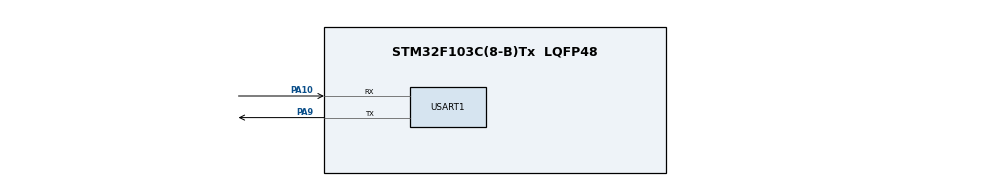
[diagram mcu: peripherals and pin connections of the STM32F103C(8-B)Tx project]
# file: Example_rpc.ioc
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FREERTOS.BinarySemaphores01=GetPacketSem,Dynamic,NULL;SendPacketSem,Dynamic,NULL
FREERTOS.Queues01=rxQueue,16,uint16_t,0,Dynamic,NULL,NULL
FREERTOS.Tasks01=defaultTask,0,128,StartDefaultTask,Default,NULL,Dynamic,NULL,NULL;linkLayerTask,2,512,LinkLayerReceive,Default,NULL,Dynamic,NULL,NULL;transpRecTask,2,512,TranspReceive,Default,NULL,Dynamic,NULL,NULL
FREERTOS.configTOTAL_HEAP_SIZE=10000
Mcu.Family=STM32F1
Mcu.Name=STM32F103C(8-B)Tx
Mcu.Package=LQFP48
NVIC.PriorityGroup=NVIC_PRIORITYGROUP_4
NVIC.TIM1_UP_IRQn=true\:15\:0\:false\:false\:true\:false\:false\:true
NVIC.TimeBase=TIM1_UP_IRQn
NVIC.TimeBaseIP=TIM1
NVIC.USART1_IRQn=true\:5\:0\:false\:false\:true\:true\:true\:true
PA10.Mode=Asynchronous
PA10.Signal=USART1_RX
PA13.Mode=Serial_Wire
PA13.Signal=SYS_JTMS-SWDIO
PA14.Mode=Serial_Wire
PA14.Signal=SYS_JTCK-SWCLK
PA9.Mode=Asynchronous
PA9.Signal=USART1_TX
PC14-OSC32_IN.Mode=LSE-External-Oscillator
PC14-OSC32_IN.Signal=RCC_OSC32_IN
PC15-OSC32_OUT.Mode=LSE-External-Oscillator
PC15-OSC32_OUT.Signal=RCC_OSC32_OUT
PD0-OSC_IN.Mode=HSE-External-Oscillator
PD0-OSC_IN.Signal=RCC_OSC_IN
PD1-OSC_OUT.Mode=HSE-External-Oscillator
PD1-OSC_OUT.Signal=RCC_OSC_OUT
ProjectManager.HeapSize=0x200
ProjectManager.StackSize=0x400
ProjectManager.TargetToolchain=STM32CubeIDE
RCC.APB1Freq_Value=8000000
RCC.APB2Freq_Value=8000000
USART1.VirtualMode=VM_ASYNC
VP_FREERTOS_VS_CMSIS_V1.Mode=CMSIS_V1
VP_SYS_VS_tim1.Mode=TIM1
board=custom

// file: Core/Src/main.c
/* USER CODE BEGIN Header */
/**
  ******************************************************************************
  * @file           : main.c
  * @brief          : Main program body
  ******************************************************************************
  * @attention
  *
  * Copyright (c) 2025 STMicroelectronics.
  * All rights reserved.
  *
  * This software is licensed under terms that can be found in the LICENSE file
  * in the root directory of this software component.
  * If no LICENSE file comes with this software, it is provided AS-IS.
  *
  ******************************************************************************
  */
/* USER CODE END Header */
#include "main.h"
#include "cmsis_os.h"
#include "usart.h"
#include "gpio.h"

void SystemClock_Config(void);
void MX_FREERTOS_Init(void);

int main(void)
{

  /* MCU Configuration--------------------------------------------------------*/

  /* Reset of all peripherals, Initializes the Flash interface and the Systick. */
  HAL_Init();

  /* Configure the system clock */
  SystemClock_Config();

  /* Initialize all configured peripherals */
  MX_GPIO_Init();
  MX_USART1_UART_Init();
  /* USER CODE BEGIN 2 */
  HAL_UARTEx_ReceiveToIdle_IT(&huart1, Buffer, 128);
  /* USER CODE END 2 */

  /* Call init function for freertos objects (in freertos.c) */
  MX_FREERTOS_Init();
  /* Start scheduler */
  osKernelStart();

  /* We should never get here as control is now taken by the scheduler */
  /* Infinite loop */
  while (1)
  {

  }
}

void SystemClock_Config(void)
{
  RCC_OscInitTypeDef RCC_OscInitStruct = {0};
  RCC_ClkInitTypeDef RCC_ClkInitStruct = {0};

  /** Initializes the RCC Oscillators according to the specified parameters
  * in the RCC_OscInitTypeDef structure.
  */
  RCC_OscInitStruct.OscillatorType = RCC_OSCILLATORTYPE_HSI;
  RCC_OscInitStruct.HSIState = RCC_HSI_ON;
  RCC_OscInitStruct.HSICalibrationValue = RCC_HSICALIBRATION_DEFAULT;
  RCC_OscInitStruct.PLL.PLLState = RCC_PLL_NONE;
  if (HAL_RCC_OscConfig(&RCC_OscInitStruct) != HAL_OK)
  {
    Error_Handler();
  }
  /** Initializes the CPU, AHB and APB buses clocks
  */
  RCC_ClkInitStruct.ClockType = RCC_CLOCKTYPE_HCLK|RCC_CLOCKTYPE_SYSCLK
                              |RCC_CLOCKTYPE_PCLK1|RCC_CLOCKTYPE_PCLK2;
  RCC_ClkInitStruct.SYSCLKSource = RCC_SYSCLKSOURCE_HSI;
  RCC_ClkInitStruct.AHBCLKDivider = RCC_SYSCLK_DIV1;
  RCC_ClkInitStruct.APB1CLKDivider = RCC_HCLK_DIV1;
  RCC_ClkInitStruct.APB2CLKDivider = RCC_HCLK_DIV1;

  if (HAL_RCC_ClockConfig(&RCC_ClkInitStruct, FLASH_LATENCY_0) != HAL_OK)
  {
    Error_Handler();
  }
}

void HAL_TIM_PeriodElapsedCallback(TIM_HandleTypeDef *htim)
{
  if (htim->Instance == TIM1) {
    HAL_IncTick();
  }
}

void Error_Handler(void)
{
  __disable_irq();
  while (1)
  {
  }
}

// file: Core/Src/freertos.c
/* USER CODE BEGIN Header */
/**
  ******************************************************************************
  * File Name          : freertos.c
  * Description        : Code for freertos applications
  ******************************************************************************
  * @attention
  *
  * Copyright (c) 2025 STMicroelectronics.
  * All rights reserved.
  *
  * This software is licensed under terms that can be found in the LICENSE file
  * in the root directory of this software component.
  * If no LICENSE file comes with this software, it is provided AS-IS.
  *
  ******************************************************************************
  */
/* USER CODE END Header */

#include "FreeRTOS.h"
#include "task.h"
#include "main.h"
#include "cmsis_os.h"

/* USER CODE BEGIN PTD */
extern UART_HandleTypeDef huart1;
/* USER CODE END PTD */

/* USER CODE BEGIN PD */
#define MAX_PACKET_SIZE 128

uint8_t crc8_calc(const uint8_t *data, uint16_t len);
bool uart_send(const uint8_t *data, uint16_t len);
bool link_layer_send(const uint8_t *payload, uint16_t payload_len);
bool transport_call(const char *name, const uint8_t *args, uint16_t args_len,
		uint8_t *resp, uint16_t *resp_len, uint32_t timeout);

void getTemp(const uint8_t* args, uint16_t args_len,uint8_t* resp, uint16_t* resp_len);
void getPressure(const uint8_t* args, uint16_t args_len,uint8_t* resp, uint16_t* resp_len);
void send_response(uint8_t seq,  uint8_t* data, uint16_t len) ;
void send_error(uint8_t seq, uint8_t error_code);

typedef void (*RPCFunction)(const uint8_t*, uint16_t, uint8_t*, uint16_t*);

typedef struct {
    uint8_t data[MAX_PACKET_SIZE];
    uint16_t length;
} Packet_t;

typedef struct {
    const char *name;
    RPCFunction func;
} FunctionEntry;

FunctionEntry functions[2] = {
		{"Get Temp",getTemp},
		{"Get Pressure",getPressure}
};
uint8_t func_count = 2;
uint8_t seq_counter = 0;
/* USER CODE END PD */

/* USER CODE BEGIN PM */

void getTemp(const uint8_t* args, uint16_t args_len,uint8_t* resp, uint16_t* resp_len)
{
	// Функция получения температуры
}
void getPressure(const uint8_t* args, uint16_t args_len, uint8_t* resp, uint16_t* resp_len)
{
	// Функция установки температуры
}

void send_response(uint8_t seq, uint8_t* data, uint16_t len)
{
    uint8_t payload[2 + len];
    payload[0] = RESPONSE; // RESPONSE
    payload[1] = seq;
    memcpy(&payload[2], data, len);
    link_layer_send(payload, 2 + len);
}

void send_error(uint8_t seq, uint8_t error_code)
{
    uint8_t payload[3];
    payload[0] = ERR;
    payload[1] = seq;
    payload[2] = error_code;
    link_layer_send(payload, 3);
}

uint8_t crc8_calc(const uint8_t *data, uint16_t len)
{
    uint8_t crc = 0x00;
    while (len--) {
        crc ^= *data++;
        for (uint8_t i = 0; i < 8; i++)
            crc = (crc & 0x80) ? ((crc << 1) ^ 0x07) : (crc << 1);
    }
    return crc;
}

bool uart_send(const uint8_t *data, uint16_t len)
{
    return HAL_UART_Transmit(&huart1, (uint8_t*)data, len, 10) == HAL_OK;
}

bool link_layer_send(const uint8_t *payload, uint16_t payload_len)
{
    // Проверка максимального размера
    if (payload_len > MAX_PACKET_SIZE - 7) return false;

    uint8_t packet[MAX_PACKET_SIZE];
    uint16_t l = 6 + payload_len;  // Длина части после 0xFA

    // Формирование заголовка
    packet[0] = 0xFA;              // Стартовый байт 1
    packet[1] = l & 0xFF;           // Младший байт длины
    packet[2] = (l >> 8) & 0xFF;    // Старший байт длины
    packet[3] = crc8_calc(&packet[1], 2); // CRC заголовка (байты 1-2)
    packet[4] = 0xFB;              // Стартовый байт 2

    // Копирование полезной нагрузки
    memcpy(&packet[5], payload, payload_len);

    // Расчет CRC всего пакета (байты 0-4 + payload)
    uint8_t crc_full = crc8_calc(packet, 5 + payload_len);
    packet[5 + payload_len] = crc_full;   // CRC payload
    packet[6 + payload_len] = 0xFE;       // Стоповый байт

    // Отправка через физический уровень
    return uart_send(packet, 7 + payload_len);
}

/* USER CODE END PM */

osThreadId defaultTaskHandle;
osThreadId linkLayerTaskHandle;
osThreadId transpRecTaskHandle;
osMessageQId rxQueueHandle;
osSemaphoreId GetPacketSemHandle;
osSemaphoreId SendPacketSemHandle;

void StartDefaultTask(void const * argument);
void LinkLayerReceive(void const * argument);
void TranspReceive(void const * argument);

void MX_FREERTOS_Init(void); /* (MISRA C 2004 rule 8.1) */

/* GetIdleTaskMemory prototype (linked to static allocation support) */
void vApplicationGetIdleTaskMemory( StaticTask_t **ppxIdleTaskTCBBuffer, StackType_t **ppxIdleTaskStackBuffer, uint32_t *pulIdleTaskStackSize );

/* USER CODE BEGIN GET_IDLE_TASK_MEMORY */
static StaticTask_t xIdleTaskTCBBuffer;
static StackType_t xIdleStack[configMINIMAL_STACK_SIZE];

void vApplicationGetIdleTaskMemory( StaticTask_t **ppxIdleTaskTCBBuffer, StackType_t **ppxIdleTaskStackBuffer, uint32_t *pulIdleTaskStackSize )
{
  *ppxIdleTaskTCBBuffer = &xIdleTaskTCBBuffer;
  *ppxIdleTaskStackBuffer = &xIdleStack[0];
  *pulIdleTaskStackSize = configMINIMAL_STACK_SIZE;
  /* place for user code */
}
/* USER CODE END GET_IDLE_TASK_MEMORY */

void MX_FREERTOS_Init(void) {

  /* Create the semaphores(s) */
  /* definition and creation of GetPacketSem */
  osSemaphoreDef(GetPacketSem);
  GetPacketSemHandle = osSemaphoreCreate(osSemaphore(GetPacketSem), 1);
  osSemaphoreWait(GetPacketSemHandle, osWaitForever);
  /* definition and creation of SendPacketSem */
  osSemaphoreDef(SendPacketSem);
  SendPacketSemHandle = osSemaphoreCreate(osSemaphore(SendPacketSem), 1);
  osSemaphoreWait(SendPacketSemHandle, osWaitForever);

  /* Create the queue(s) */
  /* definition and creation of rxQueue */
  osMessageQDef(rxQueue, 16, uint16_t);
  rxQueueHandle = osMessageCreate(osMessageQ(rxQueue), NULL);

  /* Create the thread(s) */
  /* definition and creation of defaultTask */
  osThreadDef(defaultTask, StartDefaultTask, osPriorityNormal, 0, 128);
  defaultTaskHandle = osThreadCreate(osThread(defaultTask), NULL);

  /* definition and creation of linkLayerTask */
  osThreadDef(linkLayerTask, LinkLayerReceive, osPriorityHigh, 0, 512);
  linkLayerTaskHandle = osThreadCreate(osThread(linkLayerTask), NULL);

  /* definition and creation of transpRecTask */
  osThreadDef(transpRecTask, TranspReceive, osPriorityHigh, 0, 512);
  transpRecTaskHandle = osThreadCreate(osThread(transpRecTask), NULL);

}

void StartDefaultTask(void const * argument)
{
  /* USER CODE BEGIN StartDefaultTask */
  /* Infinite loop */
  for(;;)
  {
    osDelay(1000);
  }
  /* USER CODE END StartDefaultTask */
}

void LinkLayerReceive(void const * argument)
{
  /* USER CODE BEGIN LinkLayerReceive */
    //uint8_t buffer[MAX_PACKET_SIZE];
    uint16_t length = 0, index = 0;
    uint8_t expected_crc;
    uint8_t eStatus;
    Packet_t packet;
  /* Infinite loop */
  for(;;)
  {
	osSemaphoreWait(GetPacketSemHandle, osWaitForever);

	if(Buffer[0] == 0xFA)
	{
		expected_crc = crc8_calc(&Buffer[1], 2);

		 if(expected_crc == Buffer[3])
		 {
			 length = Buffer[2]<<8 |Buffer[1];
			 index = 0;

			 if( Buffer[3] == 0xFB)
			 {
				 for(uint8_t i = 5 ;  i < length - 2 ; i++) // Учет CRC и 0xFE
				 {
					 packet.data[index++] = Buffer[i];
				 }

				 packet.length = index;

				 expected_crc = crc8_calc(&Buffer[0],length - 2);

				 if(expected_crc == Buffer[length - 2] && Buffer[length - 1] == 0xFE)
				 {
					 // Успешный прием пакета
					 eStatus = xQueueSend(rxQueueHandle, &packet, 0);
				 }
			 }

		 }
	}

	if(eStatus == 0)
	send_error(0,ERR_INVALID_ARGS); // Отправка ошибки

    osDelay(1000);
  }
  /* USER CODE END LinkLayerReceive */
}

void TranspReceive(void const * argument)
{
  /* USER CODE BEGIN TranspReceive */

  /* Infinite loop */
  for(;;)
  {
	  uint8_t packet[MAX_PACKET_SIZE];
	  uint8_t packet_len;

	  if(xQueueReceive(rxQueueHandle, &packet, portMAX_DELAY))
	  {
		 uint32_t start_time = xTaskGetTickCount();

		  Packet_t packet;
	      // Разбор пакета и вызов функции
		  uint16_t packet_len = packet.length;
		  uint8_t* data = packet.data;

		  uint8_t type = data[0];
		  uint8_t seq = data[1];

          if(seq != REQUEST  || seq != STREAM )
          {
        	  send_error(seq,ERR_FUNC_NOT_FOUND); // Отправка ошибки
          }
          else
          {
        	  // 3. Поиск терминатора имени функции
        	  uint16_t name_end_pos = 0;

        	  for(uint16_t i = 2; i < packet_len; i++)
        	  {
        		  if(data[i] == 0x00) {
        			  name_end_pos = i;
        			  break;
        		  }
        	  }
        	  // 4. Проверка наличия терминатора
        	  if(name_end_pos == 0)
        	  {
        		  send_error(seq,ERR_INVALID_ARGS); // Отправка ошибки
        		  continue;
        	  }

        	  // 5. Извлечение имени функции
        	  uint16_t name_len = name_end_pos - 2;
        	  char func_name[32];
        	  strncpy(func_name, &data[2], name_len);
        	  func_name[name_len] = '\0'; // Гарантированное завершение

        	  // 6. Извлечение аргументов
        	  uint16_t args_offset = name_end_pos + 1;
        	  uint16_t args_len = packet_len - args_offset;

        	  // Поиск функции
        	  RPCFunction func = NULL;
        	  for(int i = 0; i < func_count; i++)
        	  {
        		  if(strcmp(func_name, functions[i].name) == 0) {
        			  func = functions[i].func;
        			  break;
        		  }
        	  }
        	  // Вызов функции и отправка ответа
        	  if(func)
        	  {
        		  uint16_t resp_len = 0;
        		  uint8_t response[128];
        		  uint16_t arg_len;
        		  func(&data[args_offset], args_len ,response, &resp_len);
        	  	  // Формирование ответного пакета
        		  uint32_t elapsed = xTaskGetTickCount() - start_time;

        		  if (elapsed > FUNCTION_TIMEOUT_MS)
        		  {
        			  send_error(seq, ERR_TIMEOUT);
        		  }
        		  else
        		  {
            		  send_response(seq, response, resp_len);
        		  }

        	  }
        	  else {
        		  send_error(seq,ERR_FUNC_NOT_FOUND); // Отправка ошибки
        	  }
          }

	  }
	  osDelay(1000);
  }
  /* USER CODE END TranspReceive */
}
